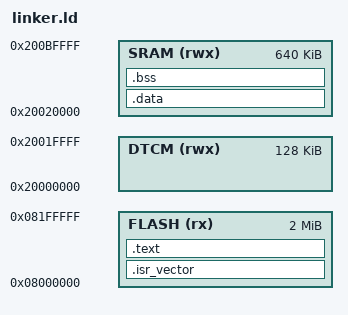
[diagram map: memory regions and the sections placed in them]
/*
 * linker.ld — Linker script for STM32H743 (CoilGrip)
 * Author: jayis1
 * Copyright (C) 2026 jayis1
 * SPDX-License-Identifier: GPL-2.0
 *
 * The STM32H743 has 2 MB flash at 0x08000000 and 1 MB SRAM.
 * We place code in flash and data/stack in DTCM/SRAM.
 */

ENTRY(Reset_Handler)

MEMORY
{
    FLASH (rx)  : ORIGIN = 0x08000000, LENGTH = 2048K
    DTCM  (rwx) : ORIGIN = 0x20000000, LENGTH = 128K
    SRAM  (rwx) : ORIGIN = 0x20020000, LENGTH = 640K
}

_estack = ORIGIN(SRAM) + LENGTH(SRAM);

SECTIONS
{
    .isr_vector : {
        . = ALIGN(4);
        KEEP(*(.isr_vector))
        . = ALIGN(4);
    } > FLASH

    .text : {
        . = ALIGN(4);
        *(.text)
        *(.text*)
        *(.rodata)
        *(.rodata*)
        . = ALIGN(4);
        _etext = .;
    } > FLASH

    .data : AT(_etext) {
        . = ALIGN(4);
        _sdata = .;
        *(.data)
        *(.data*)
        . = ALIGN(4);
        _edata = .;
    } > SRAM

    .bss (NOLOAD) : {
        . = ALIGN(4);
        _sbss = .;
        *(.bss)
        *(.bss*)
        *(COMMON)
        . = ALIGN(4);
        _ebss = .;
    } > SRAM

    /DISCARD/ : { *(.ARM.exidx*) }
}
